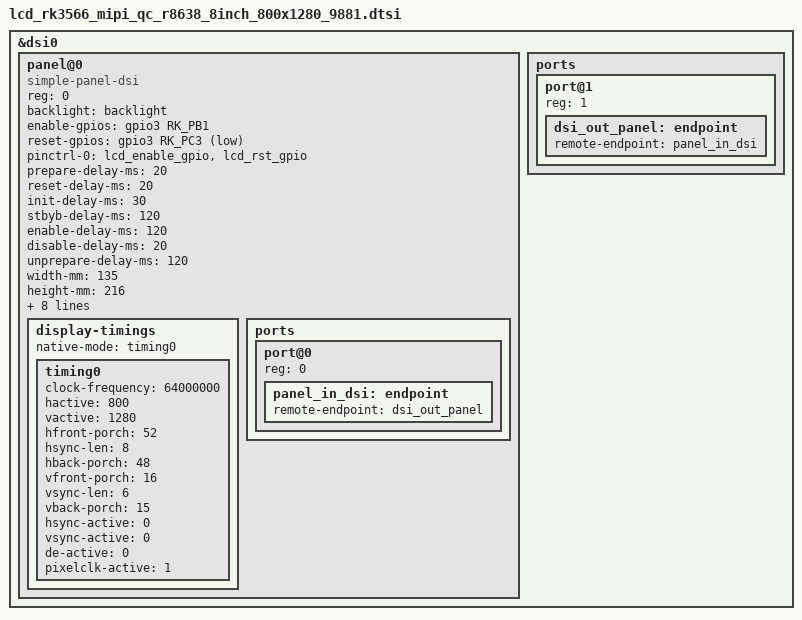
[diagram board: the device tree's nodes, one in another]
/*
* incar mipi lcd
*/
&dsi0 {
	status = "okay";
	//rockchip,lane-rate = <1000>;
	panel@0 {
		compatible = "simple-panel-dsi";
		reg = <0>;
		backlight = <&backlight>;
		//power-supply=<&vcc_3v3>;
		enable-gpios = <&gpio3 RK_PB1 GPIO_ACTIVE_HIGH>;
		//stbyb-gpios = <&gpio0 RK_PC0 GPIO_ACTIVE_LOW>;
		reset-gpios = <&gpio3 RK_PC3 GPIO_ACTIVE_LOW>;
		pinctrl-names = "default";
		pinctrl-0 = <&lcd_enable_gpio>, <&lcd_rst_gpio>;

		prepare-delay-ms = <20>;
		reset-delay-ms = <20>;
		init-delay-ms = <30>;
		stbyb-delay-ms = <120>;
		enable-delay-ms = <120>;
		disable-delay-ms = <20>;
		unprepare-delay-ms = <120>;

		width-mm = <135>;
		height-mm = <216>;

		dsi,flags = <(MIPI_DSI_MODE_VIDEO | MIPI_DSI_MODE_VIDEO_BURST |
			      MIPI_DSI_MODE_LPM | MIPI_DSI_MODE_EOT_PACKET)>;
		dsi,format = <MIPI_DSI_FMT_RGB888>;
		dsi,lanes = <4>;

		panel-init-sequence = [
39 00 04 FF 98 81 03 
//GIP_1

15 00 02 01 00 
15 00 02 02 00 
15 00 02 03 53 
15 00 02 04 53 
15 00 02 05 13 
15 00 02 06 04 
15 00 02 07 02 
15 00 02 08 02 
15 00 02 09 00 
15 00 02 0a 00 
15 00 02 0b 00 
15 00 02 0c 00 
15 00 02 0d 00 
15 00 02 0e 00 
15 00 02 0f 00 
15 00 02 10 00 
15 00 02 11 00 
15 00 02 12 00 
15 00 02 13 00 
15 00 02 14 00 
15 00 02 15 00 
15 00 02 16 00 
15 00 02 17 00 
15 00 02 18 00 
15 00 02 19 00 
15 00 02 1a 00 
15 00 02 1b 00 
15 00 02 1c 00 
15 00 02 1d 00 
15 00 02 1e c0 
15 00 02 1f 80 
15 00 02 20 02 
15 00 02 21 09 
15 00 02 22 00 
15 00 02 23 00 
15 00 02 24 00 
15 00 02 25 00 
15 00 02 26 00 
15 00 02 27 00 
15 00 02 28 55 
15 00 02 29 03 
15 00 02 2a 00 
15 00 02 2b 00 
15 00 02 2c 00 
15 00 02 2d 00 
15 00 02 2e 00 
15 00 02 2f 00 
15 00 02 30 00 
15 00 02 31 00 
15 00 02 32 00 
15 00 02 33 00 
15 00 02 34 00 
15 00 02 35 00 
15 00 02 36 00 
15 00 02 37 00 
15 00 02 38 3C 	//VDD1&2 toggle 1sec
15 00 02 39 00 
15 00 02 3a 00 
15 00 02 3b 00 
15 00 02 3c 00 
15 00 02 3d 00 
15 00 02 3e 00 
15 00 02 3f 00 
15 00 02 40 00 
15 00 02 41 00 
15 00 02 42 00 
15 00 02 43 00 
15 00 02 44 00 


//GIP_2
15 00 02 50 01 
15 00 02 51 23 
15 00 02 52 45 
15 00 02 53 67 
15 00 02 54 89 
15 00 02 55 ab 
15 00 02 56 01 
15 00 02 57 23 
15 00 02 58 45 
15 00 02 59 67 
15 00 02 5a 89 
15 00 02 5b ab 
15 00 02 5c cd 
15 00 02 5d ef 

//GIP_3
15 00 02 5e 01 
15 00 02 5f 08        //FW_GOUT_L1   STV2_ODD
15 00 02 60 02        //FW_GOUT_L2   
15 00 02 61 02        //FW_GOUT_L3
15 00 02 62  0A       //FW_GOUT_L4   RESET_ODD
15 00 02 63  15       //FW_GOUT_L5   
15 00 02 64  14       //FW_GOUT_L6   
15 00 02 65  02       //FW_GOUT_L7   
15 00 02 66  11       //FW_GOUT_L8    CK11
15 00 02 67  10       //FW_GOUT_L9    CK9
15 00 02 68  02       //FW_GOUT_L10  
15 00 02 69  0F       //FW_GOUT_L11   CK7
15 00 02 6a  0E       //FW_GOUT_L12   CK5
15 00 02 6b  02       //FW_GOUT_L13
15 00 02 6c  0D       //FW_GOUT_L14   CK3
15 00 02 6d  0C       //FW_GOUT_L15   CK1
15 00 02 6e  06       //FW_GOUT_L16   STV1_ODD
15 00 02 6f  02       //FW_GOUT_L17
15 00 02 70  02       //FW_GOUT_L18
15 00 02 71  02       //FW_GOUT_L19
15 00 02 72  02       //FW_GOUT_L20
15 00 02 73  02       //FW_GOUT_L21  
15 00 02 74  02       //FW_GOUT_L22  

15 00 02 75  06       //BW_GOUT_L1   STV2_ODD
15 00 02 76  02       //BW_GOUT_L2   
15 00 02 77  02       //BW_GOUT_L3   
15 00 02 78  0A       //BW_GOUT_L4   RESET_ODD
15 00 02 79  15       //BW_GOUT_L5   
15 00 02 7a  14       //BW_GOUT_L6   
15 00 02 7b  02       //BW_GOUT_L7   
15 00 02 7c  10       //BW_GOUT_L8    CK11
15 00 02 7d  11       //BW_GOUT_L9    CK9
15 00 02 7e  02       //BW_GOUT_L10  
15 00 02 7f  0C       //BW_GOUT_L11   CK7
15 00 02 80  0D       //BW_GOUT_L12   CK5
15 00 02 81  02       //BW_GOUT_L13
15 00 02 82  0E       //BW_GOUT_L14   CK3
15 00 02 83  0F       //BW_GOUT_L15   CK1
15 00 02 84  08       //BW_GOUT_L16   STV1_ODD
15 00 02 85  02       //BW_GOUT_L17
15 00 02 86  02       //BW_GOUT_L18
15 00 02 87  02       //BW_GOUT_L19
15 00 02 88  02       //BW_GOUT_L20
15 00 02 89  02       //BW_GOUT_L21  
15 00 02 8A  02       //BW_GOUT_L22  

//CMD_Page 4

39 00 04 FF 98 81 04 
15 00 02 6C  15
15 00 02 6E  30  //VGH clamp 16.08V
15 00 02 6F  37  // reg vcl + pumping ratio VGH=3x VGL=-3x
15 00 02 8D  1F  //VGL clamp -12.03V
15 00 02 87  BA
15 00 02 26  76
15 00 02 B2  D1
15 00 02 B5  07
15 00 02 35  17
15 00 02 33  14
15 00 02 31  75
15 00 02 3A  85
15 00 02 3B  98
15 00 02 38  01
15 00 02 39  00
15 00 02 7A  10  //VREG1/2 out

//CMD_Page 1
39 00 04 FF 98 81 01 
15 00 02 22  0A
15 00 02 31  00              //column inversion
15 00 02 50  E9		//VREG1OUT=5.508V
15 00 02 51  E4		//VREG2OUT=-5.508V
15 00 02 53  48               //VCOM1
15 00 02 55  48               //VCOM2
15 00 02 60  28		//SDT
15 00 02 2E  C8               //1280 GATE NL SEL 
15 00 02 34  01               

15 00 02 A0  00		//VP255	Gamma P
15 00 02 A1  13               //VP251        
15 00 02 A2  24               //VP247        
15 00 02 A3  15               //VP243        
15 00 02 A4  18               //VP239        
15 00 02 A5  2F               //VP231        
15 00 02 A6  22               //VP219        
15 00 02 A7  21               //VP203        
15 00 02 A8  89               //VP175        
15 00 02 A9  1B               //VP144        
15 00 02 AA  27               //VP111        
15 00 02 AB  7D               //VP80         
15 00 02 AC  1B               //VP52         
15 00 02 AD  1B               //VP36         
15 00 02 AE  50               //VP24         
15 00 02 AF  24               //VP16         
15 00 02 B0  2A               //VP12       
15 00 02 B1  51              //VP8          
15 00 02 B2  5A               //VP4          
15 00 02 B3  1B               //VP0          
                                             
15 00 02 C0  00		//VN255 GAMMA N
15 00 02 C1  16               //VN251        
15 00 02 C2  24               //VN247        
15 00 02 C3  13               //VN243        
15 00 02 C4  18               //VN239        
15 00 02 C5  2A               //VN231        
15 00 02 C6  20               //VN219        
15 00 02 C7  22               //VN203        
15 00 02 C8  80               //VN175        
15 00 02 C9  1C               //VN144        
15 00 02 CA  28               //VN111        
15 00 02 CB  71               //VN80         
15 00 02 CC  1D               //VN52         
15 00 02 CD  1B               //VN36         
15 00 02 CE  51               //VN24        
15 00 02 CF  24               //VN16         
15 00 02 D0  2A               //VN12        
15 00 02 D1  4C               //VN8          
15 00 02 D2  5A               //VN4          
15 00 02 D3  32               //VN0

39 00 04 FF 98 81 02

15 00 02 04  17 
15 00 02 05  12 
15 00 02 06  40 
15 00 02 07  0B 
39 00 04 FF 98 81 00 
15 00 02 35 00  
05 78 01 11
05 64 01 29 	 

		];

		panel-exit-sequence = [
			05 00 01 28
			05 00 01 10
		];

				
		display-timings {
			native-mode = <&timing0>;

			timing0: timing0 {
			
				clock-frequency = <64000000>;
				hactive = <800>;
				vactive = <1280>;
				hfront-porch = <52>;
				hsync-len = <8>;
				hback-porch = <48>;
				vfront-porch = <16>;
				vsync-len = <6>;
				vback-porch = <15>;
				hsync-active = <0>;
				vsync-active = <0>;
				de-active = <0>;
				pixelclk-active = <1>;
			};
		};
		ports {
			#address-cells = <1>;
			#size-cells = <0>;

			port@0 {
				reg = <0>;
				panel_in_dsi: endpoint {
					remote-endpoint = <&dsi_out_panel>;
				};
			};
		};
	};

	ports {
		#address-cells = <1>;
		#size-cells = <0>;

		port@1 {
			reg = <1>;
			dsi_out_panel: endpoint {
				remote-endpoint = <&panel_in_dsi>;
			};
		};
	};
};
